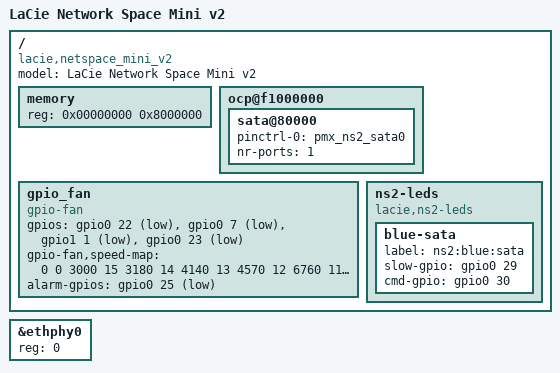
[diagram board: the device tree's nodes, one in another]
/dts-v1/;

#include "kirkwood-ns2-common.dtsi"

/ {
	/* This machine is embedded in the first LaCie CloudBox product. */
	model = "LaCie Network Space Mini v2";
	compatible = "lacie,netspace_mini_v2", "marvell,kirkwood-88f6192", "marvell,kirkwood";

	memory {
		device_type = "memory";
		reg = <0x00000000 0x8000000>;
	};

	ocp@f1000000 {
		sata@80000 {
			pinctrl-0 = <&pmx_ns2_sata0>;
			pinctrl-names = "default";
			status = "okay";
			nr-ports = <1>;
		};
	};

	gpio_fan {
		compatible = "gpio-fan";
		gpios = <&gpio0 22 GPIO_ACTIVE_LOW
			 &gpio0  7 GPIO_ACTIVE_LOW
			 &gpio1  1 GPIO_ACTIVE_LOW
			 &gpio0 23 GPIO_ACTIVE_LOW>;
		gpio-fan,speed-map =
			<   0  0
			 3000 15
			 3180 14
			 4140 13
			 4570 12
			 6760 11
			 7140 10
			 7980  9
			 9200  8>;
		alarm-gpios = <&gpio0 25 GPIO_ACTIVE_LOW>;
	};

	ns2-leds {
		compatible = "lacie,ns2-leds";

		blue-sata {
			label = "ns2:blue:sata";
			slow-gpio = <&gpio0 29 0>;
			cmd-gpio = <&gpio0 30 0>;
		};
	};
};

&ethphy0 { reg = <0>; };
